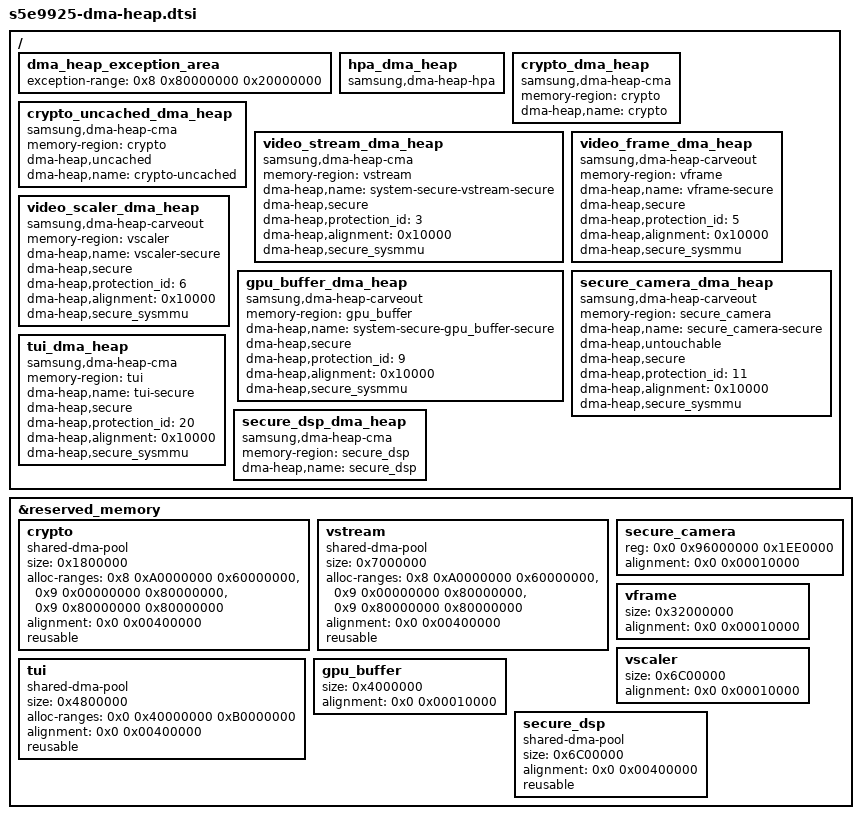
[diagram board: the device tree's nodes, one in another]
// SPDX-License-Identifier: GPL-2.0
/*
 * EXYNOS DMA HEAP device tree source for reserved-memory
 *
 * Copyright (c) 2021 Samsung Electronics Co., Ltd.
 */

/ {
	dma_heap_exception_area {
		#address-cells = <2>;
		#size-cells = <1>;
		ranges;
		exception-range = <0x8 0x80000000 0x20000000>;
	};

	hpa_dma_heap {
		compatible = "samsung,dma-heap-hpa";
	};

	crypto_dma_heap {
		compatible = "samsung,dma-heap-cma";
		memory-region = <&crypto>;
		dma-heap,name = "crypto";
	};

	crypto_uncached_dma_heap {
		compatible = "samsung,dma-heap-cma";
		memory-region = <&crypto>;
		dma-heap,uncached;
		dma-heap,name = "crypto-uncached";
	};

	video_stream_dma_heap {
		compatible = "samsung,dma-heap-cma";
		memory-region = <&vstream>;
		dma-heap,name = "system-secure-vstream-secure";
		dma-heap,secure;
		dma-heap,protection_id = <3>;
		dma-heap,alignment = <0x10000>;
		dma-heap,secure_sysmmu;
	};

	video_frame_dma_heap {
		compatible = "samsung,dma-heap-carveout";
		memory-region = <&vframe>;
		dma-heap,name = "vframe-secure";
		dma-heap,secure;
		dma-heap,protection_id = <5>;
		dma-heap,alignment = <0x10000>;
		dma-heap,secure_sysmmu;
	};

	video_scaler_dma_heap {
		compatible = "samsung,dma-heap-carveout";
		memory-region = <&vscaler>;
		dma-heap,name = "vscaler-secure";
		dma-heap,secure;
		dma-heap,protection_id = <6>;
		dma-heap,alignment = <0x10000>;
		dma-heap,secure_sysmmu;
	};

	gpu_buffer_dma_heap {
		compatible = "samsung,dma-heap-carveout";
		memory-region = <&gpu_buffer>;
		dma-heap,name = "system-secure-gpu_buffer-secure";
		dma-heap,secure;
		dma-heap,protection_id = <9>;
		dma-heap,alignment = <0x10000>;
		dma-heap,secure_sysmmu;
	};

	secure_camera_dma_heap {
		compatible = "samsung,dma-heap-carveout";
		memory-region = <&secure_camera>;
		dma-heap,name = "secure_camera-secure";
		dma-heap,untouchable;
		dma-heap,secure;
		dma-heap,protection_id = <11>;
		dma-heap,alignment = <0x10000>;
		dma-heap,secure_sysmmu;
	};

	tui_dma_heap {
		compatible = "samsung,dma-heap-cma";
		memory-region = <&tui>;
		dma-heap,name = "tui-secure";
		dma-heap,secure;
		dma-heap,protection_id = <20>;
		dma-heap,alignment = <0x10000>;
		dma-heap,secure_sysmmu;
	};

	secure_dsp_dma_heap {
		compatible = "samsung,dma-heap-cma";
		memory-region = <&secure_dsp>;
		dma-heap,name = "secure_dsp";
	};
};

&reserved_memory {
	#address-cells = <2>;
	#size-cells = <1>;

	crypto: crypto {
		compatible = "shared-dma-pool";
		size = <0x1800000>;
		alloc-ranges =	<0x8 0xA0000000 0x60000000>,
				<0x9 0x00000000 0x80000000>,
				<0x9 0x80000000 0x80000000>;
		alignment = <0x0 0x00400000>;
		reusable;
	};

	vstream: vstream {
		compatible = "shared-dma-pool";
		size = <0x7000000>;
		alloc-ranges =	<0x8 0xA0000000 0x60000000>,
				<0x9 0x00000000 0x80000000>,
				<0x9 0x80000000 0x80000000>;
		alignment = <0x0 0x00400000>;
		reusable;
	};

	tui: tui {
		compatible = "shared-dma-pool";
		size = <0x4800000>;
		alloc-ranges = <0x0 0x40000000 0xB0000000>;
		alignment = <0x0 0x00400000>;
		reusable;
	};

	secure_camera: secure_camera {
		reg = <0x0 0x96000000 0x1EE0000>;
		alignment = <0x0 0x00010000>;
	};

	vframe: vframe {
		size = <0x32000000>; /* 800M, UHD VP9: ALIGN(12,442,112 x 50 + 4.34MB, 4MB) */
		alignment = <0x0 0x00010000>;
	};

	vscaler: vscaler {
		size = <0x6C00000>;
		alignment = <0x0 0x00010000>;
	};

	gpu_buffer: gpu_buffer {
		size = <0x4000000>;
		alignment = <0x0 0x00010000>;
	};

	secure_dsp: secure_dsp {
		compatible = "shared-dma-pool";
		size = <0x6C00000>;
		alignment = <0x0 0x00400000>;
		reusable;
	};
};
